AUTOSAR XML (schema 00044)
package /E40_Platform_System_SystemPackage/Components
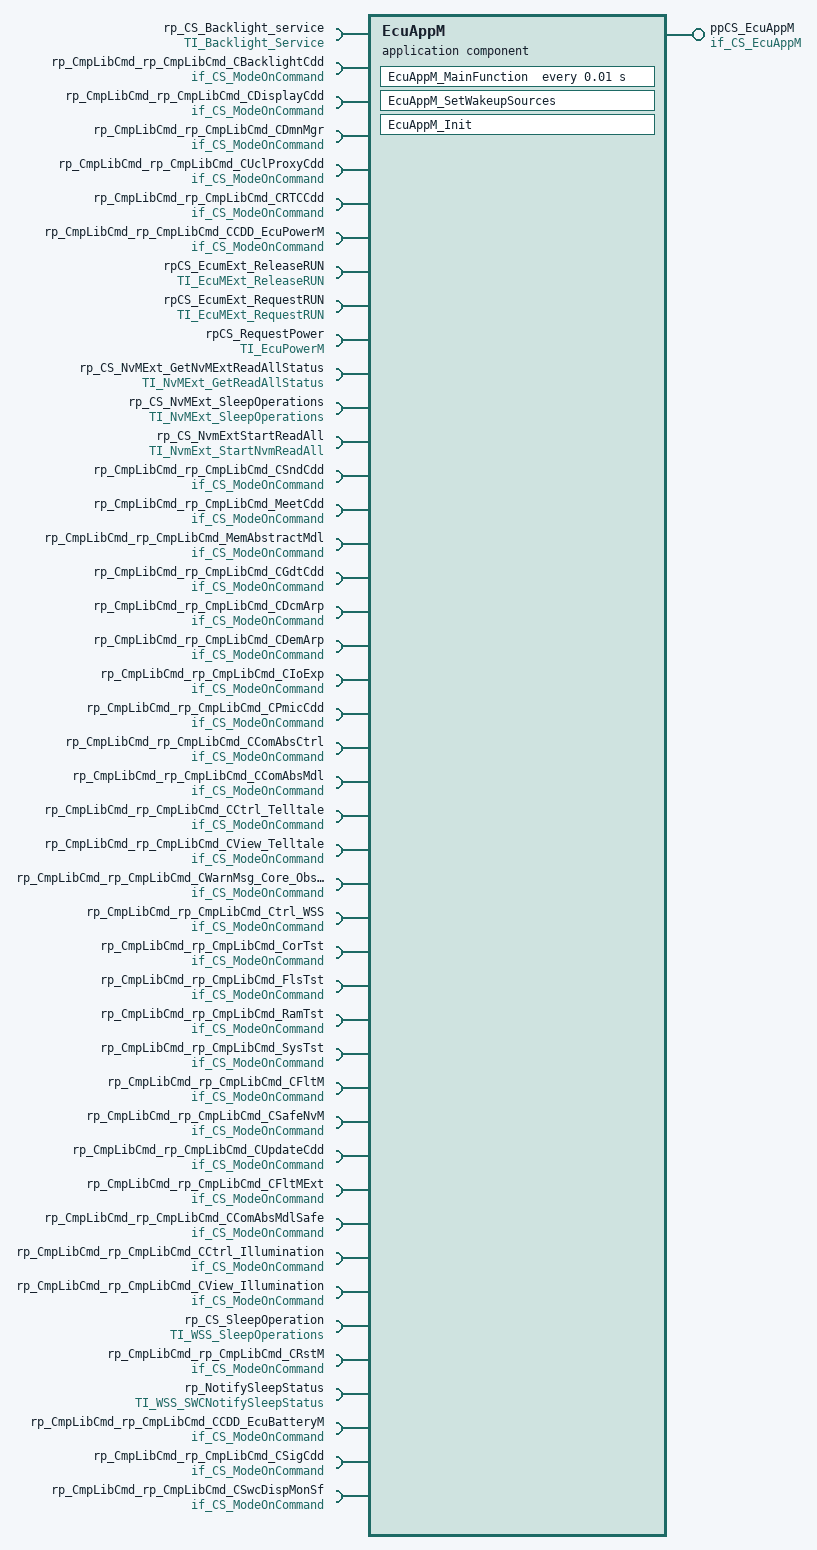
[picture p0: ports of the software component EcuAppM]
  application sw component type EcuAppM
    provide port ppCS_EcuAppM: provided-com-specs=[{operation=EcuAppM_SetWakeupSources, queue-length=1}, {operation=Init, queue-length=1}], provided-interface=if_CS_EcuAppM
    44 x require port:
      rp_CS_Backlight_service: required-com-specs=[GetBrightnessValue, GetThermalValue, SetBrightnessValue], required-interface=TI_Backlight_Service
      rp_CmpLibCmd_rp_CmpLibCmd_CBacklightCdd: client-com-spec=Impl_OnCommand, required-interface=if_CS_ModeOnCommand
      rp_CmpLibCmd_rp_CmpLibCmd_CDisplayCdd: client-com-spec=Impl_OnCommand, required-interface=if_CS_ModeOnCommand
      rp_CmpLibCmd_rp_CmpLibCmd_CDmnMgr: client-com-spec=Impl_OnCommand, required-interface=if_CS_ModeOnCommand
      rp_CmpLibCmd_rp_CmpLibCmd_CUclProxyCdd: client-com-spec=Impl_OnCommand, required-interface=if_CS_ModeOnCommand
      rp_CmpLibCmd_rp_CmpLibCmd_CRTCCdd: client-com-spec=Impl_OnCommand, required-interface=if_CS_ModeOnCommand
      rp_CmpLibCmd_rp_CmpLibCmd_CCDD_EcuPowerM: client-com-spec=Impl_OnCommand, required-interface=if_CS_ModeOnCommand
      rpCS_EcumExt_ReleaseRUN: client-com-spec=ReleaseRUN, required-interface=TI_EcuMExt_ReleaseRUN
      rpCS_EcumExt_RequestRUN: client-com-spec=RequestRUN, required-interface=TI_EcuMExt_RequestRUN
      rpCS_RequestPower: required-com-specs=[EcuPowerM_GetDeviceStatus, EcuPowerM_RequestPower], required-interface=TI_EcuPowerM
      rp_CS_NvMExt_GetNvMExtReadAllStatus: client-com-spec=NvmExt_GetNvMReadAllStatus, required-interface=TI_NvMExt_GetReadAllStatus
      rp_CS_NvMExt_SleepOperations: required-com-specs=[NvMExt_CancelSleep, NvMExt_ReadytoSleep, NvMExt_RequestSleep], required-interface=TI_NvMExt_SleepOperations
      rp_CS_NvmExtStartReadAll: client-com-spec=NvMExt_ReadAll, required-interface=TI_NvmExt_StartNvmReadAll
      rp_CmpLibCmd_rp_CmpLibCmd_CSndCdd: client-com-spec=Impl_OnCommand, required-interface=if_CS_ModeOnCommand
      rp_CmpLibCmd_rp_CmpLibCmd_MeetCdd: client-com-spec=Impl_OnCommand, required-interface=if_CS_ModeOnCommand
      rp_CmpLibCmd_rp_CmpLibCmd_MemAbstractMdl: client-com-spec=Impl_OnCommand, required-interface=if_CS_ModeOnCommand
      rp_CmpLibCmd_rp_CmpLibCmd_CGdtCdd: client-com-spec=Impl_OnCommand, required-interface=if_CS_ModeOnCommand
      rp_CmpLibCmd_rp_CmpLibCmd_CDcmArp: client-com-spec=Impl_OnCommand, required-interface=if_CS_ModeOnCommand
      rp_CmpLibCmd_rp_CmpLibCmd_CDemArp: client-com-spec=Impl_OnCommand, required-interface=if_CS_ModeOnCommand
      rp_CmpLibCmd_rp_CmpLibCmd_CIoExp: client-com-spec=Impl_OnCommand, required-interface=if_CS_ModeOnCommand
      rp_CmpLibCmd_rp_CmpLibCmd_CPmicCdd: client-com-spec=Impl_OnCommand, required-interface=if_CS_ModeOnCommand
      rp_CmpLibCmd_rp_CmpLibCmd_CComAbsCtrl: client-com-spec=Impl_OnCommand, required-interface=if_CS_ModeOnCommand
      rp_CmpLibCmd_rp_CmpLibCmd_CComAbsMdl: client-com-spec=Impl_OnCommand, required-interface=if_CS_ModeOnCommand
      rp_CmpLibCmd_rp_CmpLibCmd_CCtrl_Telltale: client-com-spec=Impl_OnCommand, required-interface=if_CS_ModeOnCommand
      rp_CmpLibCmd_rp_CmpLibCmd_CView_Telltale: client-com-spec=Impl_OnCommand, required-interface=if_CS_ModeOnCommand
      rp_CmpLibCmd_rp_CmpLibCmd_CWarnMsg_Core_Observer: client-com-spec=Impl_OnCommand, required-interface=if_CS_ModeOnCommand
      rp_CmpLibCmd_rp_CmpLibCmd_Ctrl_WSS: client-com-spec=Impl_OnCommand, required-interface=if_CS_ModeOnCommand
      rp_CmpLibCmd_rp_CmpLibCmd_CorTst: client-com-spec=Impl_OnCommand, required-interface=if_CS_ModeOnCommand
      rp_CmpLibCmd_rp_CmpLibCmd_FlsTst: client-com-spec=Impl_OnCommand, required-interface=if_CS_ModeOnCommand
      rp_CmpLibCmd_rp_CmpLibCmd_RamTst: client-com-spec=Impl_OnCommand, required-interface=if_CS_ModeOnCommand
      rp_CmpLibCmd_rp_CmpLibCmd_SysTst: client-com-spec=Impl_OnCommand, required-interface=if_CS_ModeOnCommand
      rp_CmpLibCmd_rp_CmpLibCmd_CFltM: client-com-spec=Impl_OnCommand, required-interface=if_CS_ModeOnCommand
      rp_CmpLibCmd_rp_CmpLibCmd_CSafeNvM: client-com-spec=Impl_OnCommand, required-interface=if_CS_ModeOnCommand
      rp_CmpLibCmd_rp_CmpLibCmd_CUpdateCdd: client-com-spec=Impl_OnCommand, required-interface=if_CS_ModeOnCommand
      rp_CmpLibCmd_rp_CmpLibCmd_CFltMExt: client-com-spec=Impl_OnCommand, required-interface=if_CS_ModeOnCommand
      rp_CmpLibCmd_rp_CmpLibCmd_CComAbsMdlSafe: client-com-spec=Impl_OnCommand, required-interface=if_CS_ModeOnCommand
      rp_CmpLibCmd_rp_CmpLibCmd_CCtrl_Illumination: client-com-spec=Impl_OnCommand, required-interface=if_CS_ModeOnCommand
      rp_CmpLibCmd_rp_CmpLibCmd_CView_Illumination: client-com-spec=Impl_OnCommand, required-interface=if_CS_ModeOnCommand
      rp_CS_SleepOperation: required-com-specs=[CtrlWSS_CancelSleep, CtrlWSS_ReadytoSleep, CtrlWSS_RequestSleep], required-interface=TI_WSS_SleepOperations
      rp_CmpLibCmd_rp_CmpLibCmd_CRstM: client-com-spec=Impl_OnCommand, required-interface=if_CS_ModeOnCommand
      rp_NotifySleepStatus: client-com-spec=CtrlWSS_NotifyNetworkSleep, required-interface=TI_WSS_SWCNotifySleepStatus
      rp_CmpLibCmd_rp_CmpLibCmd_CCDD_EcuBatteryM: client-com-spec=Impl_OnCommand, required-interface=if_CS_ModeOnCommand
      rp_CmpLibCmd_rp_CmpLibCmd_CSigCdd: client-com-spec=Impl_OnCommand, required-interface=if_CS_ModeOnCommand
      rp_CmpLibCmd_rp_CmpLibCmd_CSwcDispMonSf: client-com-spec=Impl_OnCommand, required-interface=if_CS_ModeOnCommand
    behavior IB_EcuAppM
      operation invoked event OIE_ppCS_EcuAppM_EcuAppM_SetWakeupSourcesTrigByEcuAppM_SetWakeupSources: start-on-event=EcuAppM_SetWakeupSources, operation=ppCS_EcuAppM.EcuAppM_SetWakeupSources
      operation invoked event OIE_ppCS_EcuAppM_EcuAppM_InitTrigByInit: start-on-event=EcuAppM_Init, operation=ppCS_EcuAppM.Init
      timing event TEEcuAppM_MainFunction: start-on-event=EcuAppM_MainFunction, period=0.01
      port-api-options:
        enable-take-address=false, indirect-api=false, port=ppCS_EcuAppM
        enable-take-address=false, indirect-api=false, port=rp_CS_Backlight_service
        enable-take-address=false, indirect-api=false, port=rp_CmpLibCmd_rp_CmpLibCmd_CBacklightCdd
        enable-take-address=false, indirect-api=false, port=rp_CmpLibCmd_rp_CmpLibCmd_CDisplayCdd
        enable-take-address=false, indirect-api=false, port=rp_CmpLibCmd_rp_CmpLibCmd_CDmnMgr
        enable-take-address=false, indirect-api=false, port=rp_CmpLibCmd_rp_CmpLibCmd_CUclProxyCdd
        enable-take-address=false, indirect-api=false, port=rp_CmpLibCmd_rp_CmpLibCmd_CRTCCdd
        enable-take-address=false, indirect-api=false, port=rp_CmpLibCmd_rp_CmpLibCmd_CCDD_EcuPowerM
        enable-take-address=false, indirect-api=false, port=rpCS_EcumExt_ReleaseRUN
        enable-take-address=false, indirect-api=false, port=rpCS_EcumExt_RequestRUN
        enable-take-address=false, indirect-api=false, port=rpCS_RequestPower
        enable-take-address=false, indirect-api=false, port=rp_CS_NvMExt_GetNvMExtReadAllStatus
        enable-take-address=false, indirect-api=false, port=rp_CS_NvMExt_SleepOperations
        enable-take-address=false, indirect-api=false, port=rp_CS_NvmExtStartReadAll
        enable-take-address=false, indirect-api=false, port=rp_CmpLibCmd_rp_CmpLibCmd_CSndCdd
        enable-take-address=false, indirect-api=false, port=rp_CmpLibCmd_rp_CmpLibCmd_MeetCdd
        enable-take-address=false, indirect-api=false, port=rp_CmpLibCmd_rp_CmpLibCmd_MemAbstractMdl
        enable-take-address=false, indirect-api=false, port=rp_CmpLibCmd_rp_CmpLibCmd_CGdtCdd
        enable-take-address=false, indirect-api=false, port=rp_CmpLibCmd_rp_CmpLibCmd_CDcmArp
        enable-take-address=false, indirect-api=false, port=rp_CmpLibCmd_rp_CmpLibCmd_CDemArp
        enable-take-address=false, indirect-api=false, port=rp_CmpLibCmd_rp_CmpLibCmd_CIoExp
        enable-take-address=false, indirect-api=false, port=rp_CmpLibCmd_rp_CmpLibCmd_CPmicCdd
        enable-take-address=false, indirect-api=false, port=rp_CmpLibCmd_rp_CmpLibCmd_CComAbsCtrl
        enable-take-address=false, indirect-api=false, port=rp_CmpLibCmd_rp_CmpLibCmd_CComAbsMdl
        enable-take-address=false, indirect-api=false, port=rp_CmpLibCmd_rp_CmpLibCmd_CCtrl_Telltale
        enable-take-address=false, indirect-api=false, port=rp_CmpLibCmd_rp_CmpLibCmd_CView_Telltale
        enable-take-address=false, indirect-api=false, port=rp_CmpLibCmd_rp_CmpLibCmd_CWarnMsg_Core_Observer
        enable-take-address=false, indirect-api=false, port=rp_CmpLibCmd_rp_CmpLibCmd_Ctrl_WSS
        enable-take-address=false, indirect-api=false, port=rp_CmpLibCmd_rp_CmpLibCmd_CorTst
        enable-take-address=false, indirect-api=false, port=rp_CmpLibCmd_rp_CmpLibCmd_FlsTst
        enable-take-address=false, indirect-api=false, port=rp_CmpLibCmd_rp_CmpLibCmd_RamTst
        enable-take-address=false, indirect-api=false, port=rp_CmpLibCmd_rp_CmpLibCmd_SysTst
        enable-take-address=false, indirect-api=false, port=rp_CmpLibCmd_rp_CmpLibCmd_CFltM
        enable-take-address=false, indirect-api=false, port=rp_CmpLibCmd_rp_CmpLibCmd_CSafeNvM
        enable-take-address=false, indirect-api=false, port=rp_CmpLibCmd_rp_CmpLibCmd_CUpdateCdd
        enable-take-address=false, indirect-api=false, port=rp_CmpLibCmd_rp_CmpLibCmd_CFltMExt
        enable-take-address=false, indirect-api=false, port=rp_CmpLibCmd_rp_CmpLibCmd_CComAbsMdlSafe
        enable-take-address=false, indirect-api=false, port=rp_CmpLibCmd_rp_CmpLibCmd_CCtrl_Illumination
        enable-take-address=false, indirect-api=false, port=rp_CmpLibCmd_rp_CmpLibCmd_CView_Illumination
        enable-take-address=false, indirect-api=false, port=rp_CS_SleepOperation
        enable-take-address=false, indirect-api=false, port=rp_CmpLibCmd_rp_CmpLibCmd_CRstM
        enable-take-address=false, indirect-api=false, port=rp_NotifySleepStatus
        enable-take-address=false, indirect-api=false, port=rp_CmpLibCmd_rp_CmpLibCmd_CCDD_EcuBatteryM
        enable-take-address=false, indirect-api=false, port=rp_CmpLibCmd_rp_CmpLibCmd_CSigCdd
        enable-take-address=false, indirect-api=false, port=rp_CmpLibCmd_rp_CmpLibCmd_CSwcDispMonSf
      runnable EcuAppM_SetWakeupSources: can-be-invoked-concurrently=true
        51 x sync call:
          OA_rp_CS_Backlight_service_SetBrightnessValue: operation=rp_CS_Backlight_service.SetBrightnessValue
          OA_rp_CS_Backlight_service_GetBrightnessValue: operation=rp_CS_Backlight_service.GetBrightnessValue
          OA_rp_CS_Backlight_service_GetThermalValue: operation=rp_CS_Backlight_service.GetThermalValue
          OA_rp_CmpLibCmd_rp_CmpLibCmd_CBacklightCdd_Impl_OnCommand: operation=rp_CmpLibCmd_rp_CmpLibCmd_CBacklightCdd.Impl_OnCommand
          OA_rp_CmpLibCmd_rp_CmpLibCmd_CDisplayCdd_Impl_OnCommand: operation=rp_CmpLibCmd_rp_CmpLibCmd_CDisplayCdd.Impl_OnCommand
          OA_rp_CmpLibCmd_rp_CmpLibCmd_CDmnMgr_Impl_OnCommand: operation=rp_CmpLibCmd_rp_CmpLibCmd_CDmnMgr.Impl_OnCommand
          OA_rp_CmpLibCmd_rp_CmpLibCmd_CUclProxyCdd_Impl_OnCommand: operation=rp_CmpLibCmd_rp_CmpLibCmd_CUclProxyCdd.Impl_OnCommand
          OA_rp_CmpLibCmd_rp_CmpLibCmd_CRTCCdd_Impl_OnCommand: operation=rp_CmpLibCmd_rp_CmpLibCmd_CRTCCdd.Impl_OnCommand
          OA_rp_CmpLibCmd_rp_CmpLibCmd_CCDD_EcuPowerM_Impl_OnCommand: operation=rp_CmpLibCmd_rp_CmpLibCmd_CCDD_EcuPowerM.Impl_OnCommand
          OA_rpCS_EcumExt_ReleaseRUN_ReleaseRUN: operation=rpCS_EcumExt_ReleaseRUN.ReleaseRUN
          OA_rpCS_EcumExt_RequestRUN_RequestRUN: operation=rpCS_EcumExt_RequestRUN.RequestRUN
          OA_rpCS_RequestPower_EcuPowerM_RequestPower: operation=rpCS_RequestPower.EcuPowerM_RequestPower
          OA_rpCS_RequestPower_EcuPowerM_GetDeviceStatus: operation=rpCS_RequestPower.EcuPowerM_GetDeviceStatus
          OA_rp_CS_NvMExt_GetNvMExtReadAllStatus_NvmExt_GetNvMReadAllStatus: operation=rp_CS_NvMExt_GetNvMExtReadAllStatus.NvmExt_GetNvMReadAllStatus
          OA_rp_CS_NvMExt_SleepOperations_NvMExt_ReadytoSleep: operation=rp_CS_NvMExt_SleepOperations.NvMExt_ReadytoSleep
          OA_rp_CS_NvMExt_SleepOperations_NvMExt_RequestSleep: operation=rp_CS_NvMExt_SleepOperations.NvMExt_RequestSleep
          OA_rp_CS_NvMExt_SleepOperations_NvMExt_CancelSleep: operation=rp_CS_NvMExt_SleepOperations.NvMExt_CancelSleep
          OA_rp_CS_NvmExtStartReadAll_NvMExt_ReadAll: operation=rp_CS_NvmExtStartReadAll.NvMExt_ReadAll
          OA_rp_CmpLibCmd_rp_CmpLibCmd_CSndCdd_Impl_OnCommand: operation=rp_CmpLibCmd_rp_CmpLibCmd_CSndCdd.Impl_OnCommand
          OA_rp_CmpLibCmd_rp_CmpLibCmd_MeetCdd_Impl_OnCommand: operation=rp_CmpLibCmd_rp_CmpLibCmd_MeetCdd.Impl_OnCommand
          OA_rp_CmpLibCmd_rp_CmpLibCmd_MemAbstractMdl_Impl_OnCommand: operation=rp_CmpLibCmd_rp_CmpLibCmd_MemAbstractMdl.Impl_OnCommand
          OA_rp_CmpLibCmd_rp_CmpLibCmd_CGdtCdd_Impl_OnCommand: operation=rp_CmpLibCmd_rp_CmpLibCmd_CGdtCdd.Impl_OnCommand
          OA_rp_CmpLibCmd_rp_CmpLibCmd_CDcmArp_Impl_OnCommand: operation=rp_CmpLibCmd_rp_CmpLibCmd_CDcmArp.Impl_OnCommand
          OA_rp_CmpLibCmd_rp_CmpLibCmd_CDemArp_Impl_OnCommand: operation=rp_CmpLibCmd_rp_CmpLibCmd_CDemArp.Impl_OnCommand
          OA_rp_CmpLibCmd_rp_CmpLibCmd_CIoExp_Impl_OnCommand: operation=rp_CmpLibCmd_rp_CmpLibCmd_CIoExp.Impl_OnCommand
          OA_rp_CmpLibCmd_rp_CmpLibCmd_CPmicCdd_Impl_OnCommand: operation=rp_CmpLibCmd_rp_CmpLibCmd_CPmicCdd.Impl_OnCommand
          OA_rp_CmpLibCmd_rp_CmpLibCmd_CComAbsCtrl_Impl_OnCommand: operation=rp_CmpLibCmd_rp_CmpLibCmd_CComAbsCtrl.Impl_OnCommand
          OA_rp_CmpLibCmd_rp_CmpLibCmd_CComAbsMdl_Impl_OnCommand: operation=rp_CmpLibCmd_rp_CmpLibCmd_CComAbsMdl.Impl_OnCommand
          OA_rp_CmpLibCmd_rp_CmpLibCmd_CCtrl_Telltale_Impl_OnCommand: operation=rp_CmpLibCmd_rp_CmpLibCmd_CCtrl_Telltale.Impl_OnCommand
          OA_rp_CmpLibCmd_rp_CmpLibCmd_CView_Telltale_Impl_OnCommand: operation=rp_CmpLibCmd_rp_CmpLibCmd_CView_Telltale.Impl_OnCommand
          OA_rp_CmpLibCmd_rp_CmpLibCmd_CWarnMsg_Core_Observer_Impl_OnCommand: operation=rp_CmpLibCmd_rp_CmpLibCmd_CWarnMsg_Core_Observer.Impl_OnCommand
          OA_rp_CmpLibCmd_rp_CmpLibCmd_Ctrl_WSS_Impl_OnCommand: operation=rp_CmpLibCmd_rp_CmpLibCmd_Ctrl_WSS.Impl_OnCommand
          OA_rp_CmpLibCmd_rp_CmpLibCmd_CorTst_Impl_OnCommand: operation=rp_CmpLibCmd_rp_CmpLibCmd_CorTst.Impl_OnCommand
          OA_rp_CmpLibCmd_rp_CmpLibCmd_FlsTst_Impl_OnCommand: operation=rp_CmpLibCmd_rp_CmpLibCmd_FlsTst.Impl_OnCommand
          OA_rp_CmpLibCmd_rp_CmpLibCmd_RamTst_Impl_OnCommand: operation=rp_CmpLibCmd_rp_CmpLibCmd_RamTst.Impl_OnCommand
          OA_rp_CmpLibCmd_rp_CmpLibCmd_SysTst_Impl_OnCommand: operation=rp_CmpLibCmd_rp_CmpLibCmd_SysTst.Impl_OnCommand
          OA_rp_CmpLibCmd_rp_CmpLibCmd_CFltM_Impl_OnCommand: operation=rp_CmpLibCmd_rp_CmpLibCmd_CFltM.Impl_OnCommand
          OA_rp_CmpLibCmd_rp_CmpLibCmd_CSafeNvM_Impl_OnCommand: operation=rp_CmpLibCmd_rp_CmpLibCmd_CSafeNvM.Impl_OnCommand
          OA_rp_CmpLibCmd_rp_CmpLibCmd_CUpdateCdd_Impl_OnCommand: operation=rp_CmpLibCmd_rp_CmpLibCmd_CUpdateCdd.Impl_OnCommand
          OA_rp_CmpLibCmd_rp_CmpLibCmd_CFltMExt_Impl_OnCommand: operation=rp_CmpLibCmd_rp_CmpLibCmd_CFltMExt.Impl_OnCommand
          OA_rp_CmpLibCmd_rp_CmpLibCmd_CComAbsMdlSafe_Impl_OnCommand: operation=rp_CmpLibCmd_rp_CmpLibCmd_CComAbsMdlSafe.Impl_OnCommand
          OA_rp_CmpLibCmd_rp_CmpLibCmd_CCtrl_Illumination_Impl_OnCommand: operation=rp_CmpLibCmd_rp_CmpLibCmd_CCtrl_Illumination.Impl_OnCommand
          OA_rp_CmpLibCmd_rp_CmpLibCmd_CView_Illumination_Impl_OnCommand: operation=rp_CmpLibCmd_rp_CmpLibCmd_CView_Illumination.Impl_OnCommand
          OA_rp_CS_SleepOperation_CtrlWSS_ReadytoSleep: operation=rp_CS_SleepOperation.CtrlWSS_ReadytoSleep
          OA_rp_CS_SleepOperation_CtrlWSS_RequestSleep: operation=rp_CS_SleepOperation.CtrlWSS_RequestSleep
          OA_rp_CS_SleepOperation_CtrlWSS_CancelSleep: operation=rp_CS_SleepOperation.CtrlWSS_CancelSleep
          OA_rp_CmpLibCmd_rp_CmpLibCmd_CRstM_Impl_OnCommand: operation=rp_CmpLibCmd_rp_CmpLibCmd_CRstM.Impl_OnCommand
          OA_rp_NotifySleepStatus_CtrlWSS_NotifyNetworkSleep: operation=rp_NotifySleepStatus.CtrlWSS_NotifyNetworkSleep
          OA_rp_CmpLibCmd_rp_CmpLibCmd_CCDD_EcuBatteryM_Impl_OnCommand: operation=rp_CmpLibCmd_rp_CmpLibCmd_CCDD_EcuBatteryM.Impl_OnCommand
          OA_rp_CmpLibCmd_rp_CmpLibCmd_CSigCdd_Impl_OnCommand: operation=rp_CmpLibCmd_rp_CmpLibCmd_CSigCdd.Impl_OnCommand
          OA_rp_CmpLibCmd_rp_CmpLibCmd_CSwcDispMonSf_Impl_OnCommand: operation=rp_CmpLibCmd_rp_CmpLibCmd_CSwcDispMonSf.Impl_OnCommand
      runnable EcuAppM_Init: can-be-invoked-concurrently=true
        51 x sync call:
          OA_rp_CS_Backlight_service_SetBrightnessValue: operation=rp_CS_Backlight_service.SetBrightnessValue
          OA_rp_CS_Backlight_service_GetBrightnessValue: operation=rp_CS_Backlight_service.GetBrightnessValue
          OA_rp_CS_Backlight_service_GetThermalValue: operation=rp_CS_Backlight_service.GetThermalValue
          OA_rp_CmpLibCmd_rp_CmpLibCmd_CBacklightCdd_Impl_OnCommand: operation=rp_CmpLibCmd_rp_CmpLibCmd_CBacklightCdd.Impl_OnCommand
          OA_rp_CmpLibCmd_rp_CmpLibCmd_CDisplayCdd_Impl_OnCommand: operation=rp_CmpLibCmd_rp_CmpLibCmd_CDisplayCdd.Impl_OnCommand
          OA_rp_CmpLibCmd_rp_CmpLibCmd_CDmnMgr_Impl_OnCommand: operation=rp_CmpLibCmd_rp_CmpLibCmd_CDmnMgr.Impl_OnCommand
          OA_rp_CmpLibCmd_rp_CmpLibCmd_CUclProxyCdd_Impl_OnCommand: operation=rp_CmpLibCmd_rp_CmpLibCmd_CUclProxyCdd.Impl_OnCommand
          OA_rp_CmpLibCmd_rp_CmpLibCmd_CRTCCdd_Impl_OnCommand: operation=rp_CmpLibCmd_rp_CmpLibCmd_CRTCCdd.Impl_OnCommand
          OA_rp_CmpLibCmd_rp_CmpLibCmd_CCDD_EcuPowerM_Impl_OnCommand: operation=rp_CmpLibCmd_rp_CmpLibCmd_CCDD_EcuPowerM.Impl_OnCommand
          OA_rpCS_EcumExt_ReleaseRUN_ReleaseRUN: operation=rpCS_EcumExt_ReleaseRUN.ReleaseRUN
          OA_rpCS_EcumExt_RequestRUN_RequestRUN: operation=rpCS_EcumExt_RequestRUN.RequestRUN
          OA_rpCS_RequestPower_EcuPowerM_RequestPower: operation=rpCS_RequestPower.EcuPowerM_RequestPower
          OA_rpCS_RequestPower_EcuPowerM_GetDeviceStatus: operation=rpCS_RequestPower.EcuPowerM_GetDeviceStatus
          OA_rp_CS_NvMExt_GetNvMExtReadAllStatus_NvmExt_GetNvMReadAllStatus: operation=rp_CS_NvMExt_GetNvMExtReadAllStatus.NvmExt_GetNvMReadAllStatus
          OA_rp_CS_NvMExt_SleepOperations_NvMExt_ReadytoSleep: operation=rp_CS_NvMExt_SleepOperations.NvMExt_ReadytoSleep
          OA_rp_CS_NvMExt_SleepOperations_NvMExt_RequestSleep: operation=rp_CS_NvMExt_SleepOperations.NvMExt_RequestSleep
          OA_rp_CS_NvMExt_SleepOperations_NvMExt_CancelSleep: operation=rp_CS_NvMExt_SleepOperations.NvMExt_CancelSleep
          OA_rp_CS_NvmExtStartReadAll_NvMExt_ReadAll: operation=rp_CS_NvmExtStartReadAll.NvMExt_ReadAll
          OA_rp_CmpLibCmd_rp_CmpLibCmd_CSndCdd_Impl_OnCommand: operation=rp_CmpLibCmd_rp_CmpLibCmd_CSndCdd.Impl_OnCommand
          OA_rp_CmpLibCmd_rp_CmpLibCmd_MeetCdd_Impl_OnCommand: operation=rp_CmpLibCmd_rp_CmpLibCmd_MeetCdd.Impl_OnCommand
          OA_rp_CmpLibCmd_rp_CmpLibCmd_MemAbstractMdl_Impl_OnCommand: operation=rp_CmpLibCmd_rp_CmpLibCmd_MemAbstractMdl.Impl_OnCommand
          OA_rp_CmpLibCmd_rp_CmpLibCmd_CGdtCdd_Impl_OnCommand: operation=rp_CmpLibCmd_rp_CmpLibCmd_CGdtCdd.Impl_OnCommand
          OA_rp_CmpLibCmd_rp_CmpLibCmd_CDcmArp_Impl_OnCommand: operation=rp_CmpLibCmd_rp_CmpLibCmd_CDcmArp.Impl_OnCommand
          OA_rp_CmpLibCmd_rp_CmpLibCmd_CDemArp_Impl_OnCommand: operation=rp_CmpLibCmd_rp_CmpLibCmd_CDemArp.Impl_OnCommand
          OA_rp_CmpLibCmd_rp_CmpLibCmd_CIoExp_Impl_OnCommand: operation=rp_CmpLibCmd_rp_CmpLibCmd_CIoExp.Impl_OnCommand
          OA_rp_CmpLibCmd_rp_CmpLibCmd_CPmicCdd_Impl_OnCommand: operation=rp_CmpLibCmd_rp_CmpLibCmd_CPmicCdd.Impl_OnCommand
          OA_rp_CmpLibCmd_rp_CmpLibCmd_CComAbsCtrl_Impl_OnCommand: operation=rp_CmpLibCmd_rp_CmpLibCmd_CComAbsCtrl.Impl_OnCommand
          OA_rp_CmpLibCmd_rp_CmpLibCmd_CComAbsMdl_Impl_OnCommand: operation=rp_CmpLibCmd_rp_CmpLibCmd_CComAbsMdl.Impl_OnCommand
          OA_rp_CmpLibCmd_rp_CmpLibCmd_CCtrl_Telltale_Impl_OnCommand: operation=rp_CmpLibCmd_rp_CmpLibCmd_CCtrl_Telltale.Impl_OnCommand
          OA_rp_CmpLibCmd_rp_CmpLibCmd_CView_Telltale_Impl_OnCommand: operation=rp_CmpLibCmd_rp_CmpLibCmd_CView_Telltale.Impl_OnCommand
          OA_rp_CmpLibCmd_rp_CmpLibCmd_CWarnMsg_Core_Observer_Impl_OnCommand: operation=rp_CmpLibCmd_rp_CmpLibCmd_CWarnMsg_Core_Observer.Impl_OnCommand
          OA_rp_CmpLibCmd_rp_CmpLibCmd_Ctrl_WSS_Impl_OnCommand: operation=rp_CmpLibCmd_rp_CmpLibCmd_Ctrl_WSS.Impl_OnCommand
          OA_rp_CmpLibCmd_rp_CmpLibCmd_CorTst_Impl_OnCommand: operation=rp_CmpLibCmd_rp_CmpLibCmd_CorTst.Impl_OnCommand
          OA_rp_CmpLibCmd_rp_CmpLibCmd_FlsTst_Impl_OnCommand: operation=rp_CmpLibCmd_rp_CmpLibCmd_FlsTst.Impl_OnCommand
          OA_rp_CmpLibCmd_rp_CmpLibCmd_RamTst_Impl_OnCommand: operation=rp_CmpLibCmd_rp_CmpLibCmd_RamTst.Impl_OnCommand
          OA_rp_CmpLibCmd_rp_CmpLibCmd_SysTst_Impl_OnCommand: operation=rp_CmpLibCmd_rp_CmpLibCmd_SysTst.Impl_OnCommand
          OA_rp_CmpLibCmd_rp_CmpLibCmd_CFltM_Impl_OnCommand: operation=rp_CmpLibCmd_rp_CmpLibCmd_CFltM.Impl_OnCommand
          OA_rp_CmpLibCmd_rp_CmpLibCmd_CSafeNvM_Impl_OnCommand: operation=rp_CmpLibCmd_rp_CmpLibCmd_CSafeNvM.Impl_OnCommand
          OA_rp_CmpLibCmd_rp_CmpLibCmd_CUpdateCdd_Impl_OnCommand: operation=rp_CmpLibCmd_rp_CmpLibCmd_CUpdateCdd.Impl_OnCommand
          OA_rp_CmpLibCmd_rp_CmpLibCmd_CFltMExt_Impl_OnCommand: operation=rp_CmpLibCmd_rp_CmpLibCmd_CFltMExt.Impl_OnCommand
          OA_rp_CmpLibCmd_rp_CmpLibCmd_CComAbsMdlSafe_Impl_OnCommand: operation=rp_CmpLibCmd_rp_CmpLibCmd_CComAbsMdlSafe.Impl_OnCommand
          OA_rp_CmpLibCmd_rp_CmpLibCmd_CCtrl_Illumination_Impl_OnCommand: operation=rp_CmpLibCmd_rp_CmpLibCmd_CCtrl_Illumination.Impl_OnCommand
          OA_rp_CmpLibCmd_rp_CmpLibCmd_CView_Illumination_Impl_OnCommand: operation=rp_CmpLibCmd_rp_CmpLibCmd_CView_Illumination.Impl_OnCommand
          OA_rp_CS_SleepOperation_CtrlWSS_ReadytoSleep: operation=rp_CS_SleepOperation.CtrlWSS_ReadytoSleep
          OA_rp_CS_SleepOperation_CtrlWSS_RequestSleep: operation=rp_CS_SleepOperation.CtrlWSS_RequestSleep
          OA_rp_CS_SleepOperation_CtrlWSS_CancelSleep: operation=rp_CS_SleepOperation.CtrlWSS_CancelSleep
          OA_rp_CmpLibCmd_rp_CmpLibCmd_CRstM_Impl_OnCommand: operation=rp_CmpLibCmd_rp_CmpLibCmd_CRstM.Impl_OnCommand
          OA_rp_NotifySleepStatus_CtrlWSS_NotifyNetworkSleep: operation=rp_NotifySleepStatus.CtrlWSS_NotifyNetworkSleep
          OA_rp_CmpLibCmd_rp_CmpLibCmd_CCDD_EcuBatteryM_Impl_OnCommand: operation=rp_CmpLibCmd_rp_CmpLibCmd_CCDD_EcuBatteryM.Impl_OnCommand
          OA_rp_CmpLibCmd_rp_CmpLibCmd_CSigCdd_Impl_OnCommand: operation=rp_CmpLibCmd_rp_CmpLibCmd_CSigCdd.Impl_OnCommand
          OA_rp_CmpLibCmd_rp_CmpLibCmd_CSwcDispMonSf_Impl_OnCommand: operation=rp_CmpLibCmd_rp_CmpLibCmd_CSwcDispMonSf.Impl_OnCommand
      runnable EcuAppM_MainFunction: can-be-invoked-concurrently=true
        51 x sync call:
          OA_rp_CS_Backlight_service_SetBrightnessValue: operation=rp_CS_Backlight_service.SetBrightnessValue
          OA_rp_CS_Backlight_service_GetBrightnessValue: operation=rp_CS_Backlight_service.GetBrightnessValue
          OA_rp_CS_Backlight_service_GetThermalValue: operation=rp_CS_Backlight_service.GetThermalValue
          OA_rp_CmpLibCmd_rp_CmpLibCmd_CBacklightCdd_Impl_OnCommand: operation=rp_CmpLibCmd_rp_CmpLibCmd_CBacklightCdd.Impl_OnCommand
          OA_rp_CmpLibCmd_rp_CmpLibCmd_CDisplayCdd_Impl_OnCommand: operation=rp_CmpLibCmd_rp_CmpLibCmd_CDisplayCdd.Impl_OnCommand
          OA_rp_CmpLibCmd_rp_CmpLibCmd_CDmnMgr_Impl_OnCommand: operation=rp_CmpLibCmd_rp_CmpLibCmd_CDmnMgr.Impl_OnCommand
          OA_rp_CmpLibCmd_rp_CmpLibCmd_CUclProxyCdd_Impl_OnCommand: operation=rp_CmpLibCmd_rp_CmpLibCmd_CUclProxyCdd.Impl_OnCommand
          OA_rp_CmpLibCmd_rp_CmpLibCmd_CRTCCdd_Impl_OnCommand: operation=rp_CmpLibCmd_rp_CmpLibCmd_CRTCCdd.Impl_OnCommand
          OA_rp_CmpLibCmd_rp_CmpLibCmd_CCDD_EcuPowerM_Impl_OnCommand: operation=rp_CmpLibCmd_rp_CmpLibCmd_CCDD_EcuPowerM.Impl_OnCommand
          OA_rpCS_EcumExt_ReleaseRUN_ReleaseRUN: operation=rpCS_EcumExt_ReleaseRUN.ReleaseRUN
          OA_rpCS_EcumExt_RequestRUN_RequestRUN: operation=rpCS_EcumExt_RequestRUN.RequestRUN
          OA_rpCS_RequestPower_EcuPowerM_RequestPower: operation=rpCS_RequestPower.EcuPowerM_RequestPower
          OA_rpCS_RequestPower_EcuPowerM_GetDeviceStatus: operation=rpCS_RequestPower.EcuPowerM_GetDeviceStatus
          OA_rp_CS_NvMExt_GetNvMExtReadAllStatus_NvmExt_GetNvMReadAllStatus: operation=rp_CS_NvMExt_GetNvMExtReadAllStatus.NvmExt_GetNvMReadAllStatus
          OA_rp_CS_NvMExt_SleepOperations_NvMExt_ReadytoSleep: operation=rp_CS_NvMExt_SleepOperations.NvMExt_ReadytoSleep
          OA_rp_CS_NvMExt_SleepOperations_NvMExt_RequestSleep: operation=rp_CS_NvMExt_SleepOperations.NvMExt_RequestSleep
          OA_rp_CS_NvMExt_SleepOperations_NvMExt_CancelSleep: operation=rp_CS_NvMExt_SleepOperations.NvMExt_CancelSleep
          OA_rp_CS_NvmExtStartReadAll_NvMExt_ReadAll: operation=rp_CS_NvmExtStartReadAll.NvMExt_ReadAll
          OA_rp_CmpLibCmd_rp_CmpLibCmd_CSndCdd_Impl_OnCommand: operation=rp_CmpLibCmd_rp_CmpLibCmd_CSndCdd.Impl_OnCommand
          OA_rp_CmpLibCmd_rp_CmpLibCmd_MeetCdd_Impl_OnCommand: operation=rp_CmpLibCmd_rp_CmpLibCmd_MeetCdd.Impl_OnCommand
          OA_rp_CmpLibCmd_rp_CmpLibCmd_MemAbstractMdl_Impl_OnCommand: operation=rp_CmpLibCmd_rp_CmpLibCmd_MemAbstractMdl.Impl_OnCommand
          OA_rp_CmpLibCmd_rp_CmpLibCmd_CGdtCdd_Impl_OnCommand: operation=rp_CmpLibCmd_rp_CmpLibCmd_CGdtCdd.Impl_OnCommand
          OA_rp_CmpLibCmd_rp_CmpLibCmd_CDcmArp_Impl_OnCommand: operation=rp_CmpLibCmd_rp_CmpLibCmd_CDcmArp.Impl_OnCommand
          OA_rp_CmpLibCmd_rp_CmpLibCmd_CDemArp_Impl_OnCommand: operation=rp_CmpLibCmd_rp_CmpLibCmd_CDemArp.Impl_OnCommand
          OA_rp_CmpLibCmd_rp_CmpLibCmd_CIoExp_Impl_OnCommand: operation=rp_CmpLibCmd_rp_CmpLibCmd_CIoExp.Impl_OnCommand
          OA_rp_CmpLibCmd_rp_CmpLibCmd_CPmicCdd_Impl_OnCommand: operation=rp_CmpLibCmd_rp_CmpLibCmd_CPmicCdd.Impl_OnCommand
          OA_rp_CmpLibCmd_rp_CmpLibCmd_CComAbsCtrl_Impl_OnCommand: operation=rp_CmpLibCmd_rp_CmpLibCmd_CComAbsCtrl.Impl_OnCommand
          OA_rp_CmpLibCmd_rp_CmpLibCmd_CComAbsMdl_Impl_OnCommand: operation=rp_CmpLibCmd_rp_CmpLibCmd_CComAbsMdl.Impl_OnCommand
          OA_rp_CmpLibCmd_rp_CmpLibCmd_CCtrl_Telltale_Impl_OnCommand: operation=rp_CmpLibCmd_rp_CmpLibCmd_CCtrl_Telltale.Impl_OnCommand
          OA_rp_CmpLibCmd_rp_CmpLibCmd_CView_Telltale_Impl_OnCommand: operation=rp_CmpLibCmd_rp_CmpLibCmd_CView_Telltale.Impl_OnCommand
          OA_rp_CmpLibCmd_rp_CmpLibCmd_CWarnMsg_Core_Observer_Impl_OnCommand: operation=rp_CmpLibCmd_rp_CmpLibCmd_CWarnMsg_Core_Observer.Impl_OnCommand
          OA_rp_CmpLibCmd_rp_CmpLibCmd_Ctrl_WSS_Impl_OnCommand: operation=rp_CmpLibCmd_rp_CmpLibCmd_Ctrl_WSS.Impl_OnCommand
          OA_rp_CmpLibCmd_rp_CmpLibCmd_CorTst_Impl_OnCommand: operation=rp_CmpLibCmd_rp_CmpLibCmd_CorTst.Impl_OnCommand
          OA_rp_CmpLibCmd_rp_CmpLibCmd_FlsTst_Impl_OnCommand: operation=rp_CmpLibCmd_rp_CmpLibCmd_FlsTst.Impl_OnCommand
          OA_rp_CmpLibCmd_rp_CmpLibCmd_RamTst_Impl_OnCommand: operation=rp_CmpLibCmd_rp_CmpLibCmd_RamTst.Impl_OnCommand
          OA_rp_CmpLibCmd_rp_CmpLibCmd_SysTst_Impl_OnCommand: operation=rp_CmpLibCmd_rp_CmpLibCmd_SysTst.Impl_OnCommand
          OA_rp_CmpLibCmd_rp_CmpLibCmd_CFltM_Impl_OnCommand: operation=rp_CmpLibCmd_rp_CmpLibCmd_CFltM.Impl_OnCommand
          OA_rp_CmpLibCmd_rp_CmpLibCmd_CSafeNvM_Impl_OnCommand: operation=rp_CmpLibCmd_rp_CmpLibCmd_CSafeNvM.Impl_OnCommand
          OA_rp_CmpLibCmd_rp_CmpLibCmd_CUpdateCdd_Impl_OnCommand: operation=rp_CmpLibCmd_rp_CmpLibCmd_CUpdateCdd.Impl_OnCommand
          OA_rp_CmpLibCmd_rp_CmpLibCmd_CFltMExt_Impl_OnCommand: operation=rp_CmpLibCmd_rp_CmpLibCmd_CFltMExt.Impl_OnCommand
          OA_rp_CmpLibCmd_rp_CmpLibCmd_CComAbsMdlSafe_Impl_OnCommand: operation=rp_CmpLibCmd_rp_CmpLibCmd_CComAbsMdlSafe.Impl_OnCommand
          OA_rp_CmpLibCmd_rp_CmpLibCmd_CCtrl_Illumination_Impl_OnCommand: operation=rp_CmpLibCmd_rp_CmpLibCmd_CCtrl_Illumination.Impl_OnCommand
          OA_rp_CmpLibCmd_rp_CmpLibCmd_CView_Illumination_Impl_OnCommand: operation=rp_CmpLibCmd_rp_CmpLibCmd_CView_Illumination.Impl_OnCommand
          OA_rp_CS_SleepOperation_CtrlWSS_ReadytoSleep: operation=rp_CS_SleepOperation.CtrlWSS_ReadytoSleep
          OA_rp_CS_SleepOperation_CtrlWSS_RequestSleep: operation=rp_CS_SleepOperation.CtrlWSS_RequestSleep
          OA_rp_CS_SleepOperation_CtrlWSS_CancelSleep: operation=rp_CS_SleepOperation.CtrlWSS_CancelSleep
          OA_rp_CmpLibCmd_rp_CmpLibCmd_CRstM_Impl_OnCommand: operation=rp_CmpLibCmd_rp_CmpLibCmd_CRstM.Impl_OnCommand
          OA_rp_NotifySleepStatus_CtrlWSS_NotifyNetworkSleep: operation=rp_NotifySleepStatus.CtrlWSS_NotifyNetworkSleep
          OA_rp_CmpLibCmd_rp_CmpLibCmd_CCDD_EcuBatteryM_Impl_OnCommand: operation=rp_CmpLibCmd_rp_CmpLibCmd_CCDD_EcuBatteryM.Impl_OnCommand
          OA_rp_CmpLibCmd_rp_CmpLibCmd_CSigCdd_Impl_OnCommand: operation=rp_CmpLibCmd_rp_CmpLibCmd_CSigCdd.Impl_OnCommand
          OA_rp_CmpLibCmd_rp_CmpLibCmd_CSwcDispMonSf_Impl_OnCommand: operation=rp_CmpLibCmd_rp_CmpLibCmd_CSwcDispMonSf.Impl_OnCommand
  swc implementation IMPL_EcuAppM: behavior=IB_EcuAppM
